VERSION ""

NS_ :

BS_:

BU_: VCU ACDB_MCU
VAL_TABLE_ Serial_Rev 90 "Z" 89 "Y" 88 "X" 87 "W" 86 "V" 85 "U" 84 "T" 83 "S" 82 "R" 81 "Q" 80 "P" 79 "O" 78 "N" 77 "M" 76 "L" 75 "K" 74 "J" 73 "I" 72 "H" 71 "G" 70 "F" 69 "E" 68 "D" 67 "C" 66 "B" 65 "A" ;
VAL_TABLE_ MCU_Status 1 "ON" 0 "OFF" ;
VAL_TABLE_ CCS_Detect 1 "EU-Region" 0 "Not-EU" ;
VAL_TABLE_ J1772_Detect 1 "US-Region" 0 "Not-US" ;
VAL_TABLE_ PP_D0 1 "Locked" 0 "Unlocked" ;
VAL_TABLE_ PP_D1 1 "Detected" 0 "Unconnected" ;
VAL_TABLE_ Switch_Status 1 "ON" 0 "OFF" ;
VAL_TABLE_ nFault 1 "No Fault" 0 "Fault Present" ;

BO_ 2667708864 BL_CallApplication: 8 VCU
 SG_ BL_CallApp_Signal : 0|64@1+ (1,0) [0|1.84467440737096E+019] "" Vector__XXX

BO_ 2667708800 BL_Request: 8 VCU

BO_ 2667708672 BL_Acknowledge: 1 VCU
 SG_ BL_Ack_Signal : 0|8@1+ (1,0) [0|255] "" Vector__XXX

BO_ 2667708608 BL_Reset: 8 VCU
 SG_ BL_Reset_Signal : 0|64@1+ (1,0) [0|1.84467440737096E+019] "" Vector__XXX

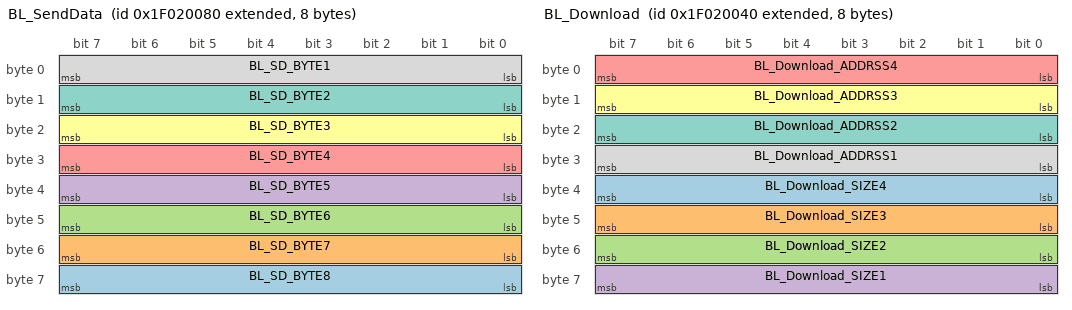
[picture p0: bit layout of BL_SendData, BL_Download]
BO_ 2667708544 BL_SendData: 8 VCU
 SG_ BL_SD_BYTE8 : 56|8@1- (1,0) [0|0] ""  ACDB_MCU
 SG_ BL_SD_BYTE7 : 48|8@1- (1,0) [0|0] ""  ACDB_MCU
 SG_ BL_SD_BYTE6 : 40|8@1- (1,0) [0|0] ""  ACDB_MCU
 SG_ BL_SD_BYTE5 : 32|8@1- (1,0) [0|0] ""  ACDB_MCU
 SG_ BL_SD_BYTE4 : 24|8@1- (1,0) [0|0] ""  ACDB_MCU
 SG_ BL_SD_BYTE3 : 16|8@1- (1,0) [0|0] ""  ACDB_MCU
 SG_ BL_SD_BYTE2 : 8|8@1- (1,0) [0|0] ""  ACDB_MCU
 SG_ BL_SD_BYTE1 : 0|8@1- (1,0) [0|0] ""  ACDB_MCU

BO_ 2667708480 BL_Download: 8 VCU
 SG_ BL_Download_SIZE4 : 32|8@1- (1,0) [0|0] "NA" Vector__XXX
 SG_ BL_Download_SIZE3 : 40|8@1- (1,0) [0|0] "NA" Vector__XXX
 SG_ BL_Download_SIZE2 : 48|8@1- (1,0) [0|0] "NA" Vector__XXX
 SG_ BL_Download_SIZE1 : 56|8@1- (1,0) [0|0] "NA" Vector__XXX
 SG_ BL_Download_ADDRSS4 : 0|8@1- (1,0) [0|0] "NA"  ACDB_MCU
 SG_ BL_Download_ADDRSS3 : 8|8@1- (1,0) [0|0] "NA"  ACDB_MCU
 SG_ BL_Download_ADDRSS2 : 16|8@1- (1,0) [0|0] "NA"  ACDB_MCU
 SG_ BL_Download_ADDRSS1 : 24|8@1- (1,0) [0|0] "NA"  ACDB_MCU

BO_ 2667708416 BL_Ping: 8 VCU
 SG_ BL_Ping_Signal : 0|64@1+ (1,0) [0|1.84467440737096E+019] "" Vector__XXX

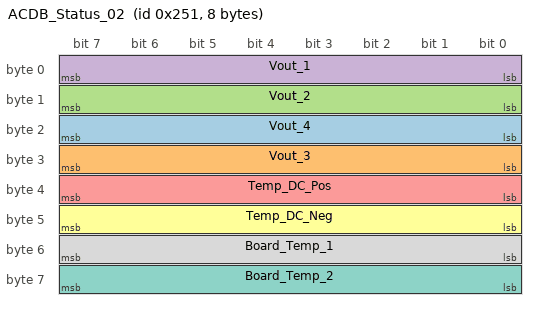
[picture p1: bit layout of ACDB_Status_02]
BO_ 593 ACDB_Status_02: 8 ACDB_MCU
 SG_ Vout_4 : 16|8@1+ (0.333333333333333,0) [0|85] "A"  VCU
 SG_ Vout_3 : 24|8@1+ (0.333333333333333,0) [0|85] "A"  VCU
 SG_ Vout_2 : 8|8@1+ (0.333333333333333,0) [0|85] "A"  VCU
 SG_ Vout_1 : 0|8@1+ (0.333333333333333,0) [0|85] "A"  VCU
 SG_ Temp_DC_Pos : 32|8@1+ (0.5,-30) [-30|97.5] "degC"  VCU
 SG_ Temp_DC_Neg : 40|8@1+ (0.5,-30) [-30|97.5] "degC"  VCU
 SG_ Board_Temp_2 : 56|8@1+ (0.7647,-40) [-40|154.9985] "degC"  VCU
 SG_ Board_Temp_1 : 48|8@1+ (0.7647,-40) [-40|154.9985] "degC"  VCU

BO_ 597 VCU_Command_01: 8 VCU
 SG_ nDEMUX_En m0 : 23|1@1+ (1,0) [0|1] "" Vector__XXX
 SG_ Reset_MCU m0 : 15|1@1+ (1,0) [0|1] "" Vector__XXX
 SG_ Serial_SupplierCode_cmd m2 : 32|24@1+ (1,0) [0|16777215] "" Vector__XXX
 SG_ Serial_SerialNo_cmd m1 : 17|20@1+ (1,0) [0|1048575] "" Vector__XXX
 SG_ Serial_Rev_cmd m2 : 24|8@1+ (1,0) [0|255] "" Vector__XXX
 SG_ Serial_PartNumber_1_cmd m2 : 16|8@1+ (1,0) [0|255] "" Vector__XXX
 SG_ Serial_PartNumber_2_cmd m2 : 0|14@1+ (1,0) [0|16383] "" Vector__XXX
 SG_ Serial_JulianDate_cmd m1 : 0|17@1+ (1,0) [0|131071] "" Vector__XXX
 SG_ Multiplexor_255 M : 62|2@1+ (1,0) [0|3] "" Vector__XXX
 SG_ nOC_Fault_Clear m0 : 1|1@1+ (1,0) [0|1] ""  ACDB_MCU
 SG_ Motor_Ctrl_2 m0 : 32|7@1+ (1,0) [0|127] ""  ACDB_MCU
 SG_ Motor_Ctrl_1 m0 : 24|7@1+ (1,0) [0|127] ""  ACDB_MCU
 SG_ D_Select m0 : 7|1@1+ (1,0) [0|1] ""  ACDB_MCU
 SG_ C_Select m0 : 6|1@1+ (1,0) [0|1] ""  ACDB_MCU
 SG_ B2B3_Select m0 : 5|1@1+ (1,0) [0|1] ""  ACDB_MCU
 SG_ B1_Select m0 : 4|1@1+ (1,0) [0|1] ""  ACDB_MCU
 SG_ A2A3_Select m0 : 3|1@1+ (1,0) [0|1] ""  ACDB_MCU
 SG_ A1_Select m0 : 2|1@1+ (1,0) [0|1] ""  ACDB_MCU
 SG_ Charge_Enable m0 : 0|1@1+ (1,0) [0|1] ""  ACDB_MCU
 SG_ PE_Fan_Ctrl m0 : 8|7@1+ (1,0) [0|127] "%"  ACDB_MCU
 SG_ Hyd_Fan_Ctrl m0 : 16|7@1+ (1,0) [0|127] "%"  ACDB_MCU

BO_ 592 ACDB_Status_01: 8 ACDB_MCU
 SG_ OCD_Ext_4 m0 : 30|1@1+ (1,0) [0|1] "" Vector__XXX
 SG_ OCD_Ext_3 m0 : 29|1@1+ (1,0) [0|1] "" Vector__XXX
 SG_ OCD_Ext_2 m0 : 28|1@1+ (1,0) [0|1] "" Vector__XXX
 SG_ OCD_Ext_1 m0 : 27|1@1+ (1,0) [0|1] "" Vector__XXX
 SG_ MCU_Status m0 : 24|1@1+ (1,0) [0|1] "" Vector__XXX
 SG_ EVSE_PP_D1 m0 : 25|1@1+ (1,0) [0|1] "" Vector__XXX
 SG_ EVSE_PP_D0 m0 : 26|1@1+ (1,0) [0|1] "" Vector__XXX
 SG_ D_Select_Probe m0 : 22|1@1+ (1,0) [0|1] "" Vector__XXX
 SG_ ChgEnable_Probe m0 : 23|1@1+ (1,0) [0|1] "" Vector__XXX
 SG_ C_Select_Probe m0 : 21|1@1+ (1,0) [0|1] "" Vector__XXX
 SG_ B2B3_Select_Probe m0 : 20|1@1+ (1,0) [0|1] "" Vector__XXX
 SG_ B1_Select_Probe m0 : 19|1@1+ (1,0) [0|1] "" Vector__XXX
 SG_ A2A3_Select_Probe m0 : 18|1@1+ (1,0) [0|1] "" Vector__XXX
 SG_ A1_Select_Probe m0 : 17|1@1+ (1,0) [0|1] "" Vector__XXX
 SG_ ChargeEnable_Status m0 : 16|1@1+ (1,0) [0|1] "" Vector__XXX
 SG_ Fault_Codes m0 : 48|8@1+ (1,0) [0|255] "" Vector__XXX
 SG_ Serial_PartNumber_2 m2 : 40|14@1+ (1,0) [0|16383] "" Vector__XXX
 SG_ Serial_PartNumber_1 m2 : 32|8@1+ (1,0) [0|255] "" Vector__XXX
 SG_ Serial_Rev m2 : 56|8@1+ (1,0) [0|255] "" Vector__XXX
 SG_ Serial_SupplierCode m2 : 8|24@1+ (1,0) [0|16777215] "" Vector__XXX
 SG_ Serial_JulianDate m1 : 8|17@1+ (1,0) [0|131071] "" Vector__XXX
 SG_ Serial_SerialNo m1 : 25|20@1+ (1,0) [0|1048575] "" Vector__XXX
 SG_ Multiplexor_250 M : 0|2@1+ (1,0) [0|3] "" Vector__XXX
 SG_ Firmware_version m0 : 56|8@1+ (0.1,0) [0|25.5] ""  VCU
 SG_ nFuse_Fault2 m0 : 15|1@1+ (1,0) [0|1] ""  VCU
 SG_ nFuse_Fault1 m0 : 14|1@1+ (1,0) [0|1] ""  VCU
 SG_ nHVILIN_Fault m0 : 12|1@1+ (1,0) [0|1] ""  VCU
 SG_ nHVIL_Fault m0 : 13|1@1+ (1,0) [0|1] ""  VCU
 SG_ J1772_Detect m0 : 10|1@1+ (1,0) [0|1] ""  VCU
 SG_ CCS_Detect m0 : 11|1@1+ (1,0) [0|1] ""  VCU
 SG_ EVSE_CP m0 : 33|7@1+ (1,0) [0|127] "%"  VCU
 SG_ EVSE_PP m0 : 40|8@1+ (0.015,0) [0|3.825] "V"  VCU
 SG_ D_Status m0 : 9|1@1+ (1,0) [0|1] ""  VCU
 SG_ C_Status m0 : 8|1@1+ (1,0) [0|1] ""  VCU
 SG_ B3_Status m0 : 7|1@1+ (1,0) [0|1] ""  VCU
 SG_ B2_Status m0 : 6|1@1+ (1,0) [0|1] ""  VCU
 SG_ B1_Status m0 : 5|1@1+ (1,0) [0|1] ""  VCU
 SG_ A3_Status m0 : 4|1@1+ (1,0) [0|1] ""  VCU
 SG_ A2_Status m0 : 3|1@1+ (1,0) [0|1] ""  VCU
 SG_ A1_Status m0 : 2|1@1+ (1,0) [0|1] ""  VCU

BA_DEF_  "BusType" STRING ;
BA_DEF_ SG_  "GenSigStartValue" FLOAT -3.4E+038 3.4E+038;
BA_DEF_DEF_  "BusType" "CAN";
BA_DEF_DEF_  "GenSigStartValue" 0;
BA_ "GenSigStartValue" SG_ 593 Temp_DC_Pos 60;
BA_ "GenSigStartValue" SG_ 593 Temp_DC_Neg 60;
BA_ "GenSigStartValue" SG_ 593 Board_Temp_2 52.2875816993464;
BA_ "GenSigStartValue" SG_ 593 Board_Temp_1 52.2875816993464;
VAL_ 592 MCU_Status 1 "ON" 0 "OFF" ;
VAL_ 592 EVSE_PP_D1 1 "Detected" 0 "Unconnected" ;
VAL_ 592 EVSE_PP_D0 1 "Locked" 0 "Unlocked" ;
VAL_ 592 ChargeEnable_Status 1 "ON" 0 "OFF" ;
VAL_ 592 Serial_Rev 90 "Z" 89 "Y" 88 "X" 87 "W" 86 "V" 85 "U" 84 "T" 83 "S" 82 "R" 81 "Q" 80 "P" 79 "O" 78 "N" 77 "M" 76 "L" 75 "K" 74 "J" 73 "I" 72 "H" 71 "G" 70 "F" 69 "E" 68 "D" 67 "C" 66 "B" 65 "A" ;
VAL_ 592 nFuse_Fault2 1 "No Fault" 0 "Fault Present" ;
VAL_ 592 nFuse_Fault1 1 "No Fault" 0 "Fault Present" ;
VAL_ 592 nHVILIN_Fault 1 "No Fault" 0 "Fault Present" ;
VAL_ 592 nHVIL_Fault 1 "No Fault" 0 "Fault Present" ;
VAL_ 592 J1772_Detect 1 "US-Region" 0 "Not-US" ;
VAL_ 592 CCS_Detect 1 "EU-Region" 0 "Not-EU" ;
VAL_ 592 D_Status 1 "ON" 0 "OFF" ;
VAL_ 592 C_Status 1 "ON" 0 "OFF" ;
VAL_ 592 B3_Status 1 "ON" 0 "OFF" ;
VAL_ 592 B2_Status 1 "ON" 0 "OFF" ;
VAL_ 592 B1_Status 1 "ON" 0 "OFF" ;
VAL_ 592 A3_Status 1 "ON" 0 "OFF" ;
VAL_ 592 A2_Status 1 "ON" 0 "OFF" ;
VAL_ 592 A1_Status 1 "ON" 0 "OFF" ;
